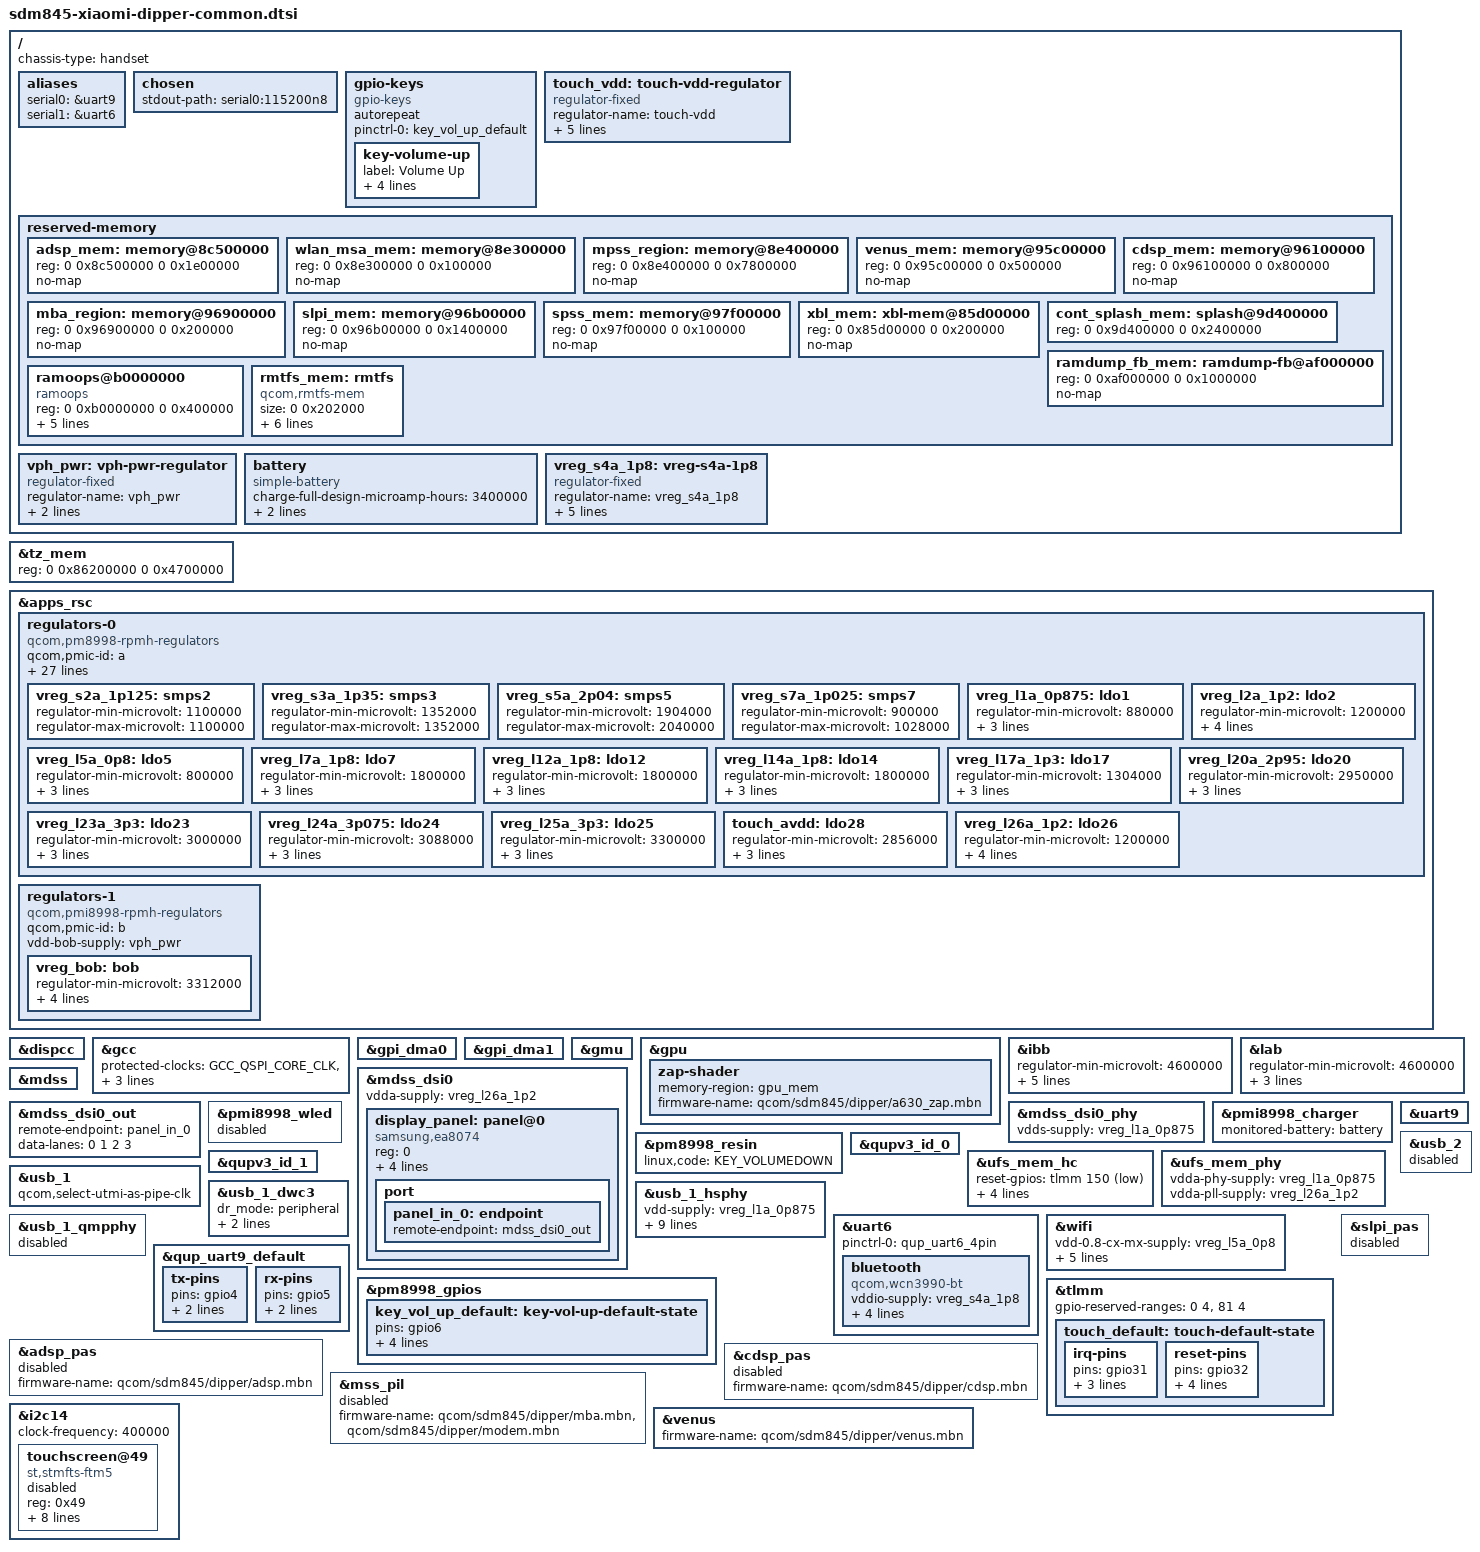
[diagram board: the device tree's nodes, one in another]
// SPDX-License-Identifier: GPL-2.0
/*
 * Xiaomi Mi 8 (dipper), shared v2/v2.1 board description.
 * Derived from Max Furman's dipper-mainline-port board description.
 * Copyright (c) 2026 Max Furman <taygoth@gmail.com>
 *
 * This source is compile-tested only. It is not a tested boot image.
 * Camera, audio, fuel gauge and Type-C role/PD support need separate
 * drivers/integration; do not enable placeholder nodes for them here.
 */

#include <dt-bindings/arm/qcom,ids.h>
#include <dt-bindings/firmware/qcom,scm.h>
#include <dt-bindings/gpio/gpio.h>
#include <dt-bindings/input/linux-event-codes.h>
#include <dt-bindings/interrupt-controller/irq.h>
#include <dt-bindings/phy/phy-qcom-qusb2.h>
#include <dt-bindings/pinctrl/qcom,pmic-gpio.h>
#include <dt-bindings/regulator/qcom,rpmh-regulator.h>
#include "sdm845.dtsi"
#include "pm8998.dtsi"
#include "pmi8998.dtsi"

/delete-node/ &xbl_mem;
/delete-node/ &rmtfs_mem;
/delete-node/ &adsp_mem;
/delete-node/ &wlan_msa_mem;
/delete-node/ &mpss_region;
/delete-node/ &venus_mem;
/delete-node/ &cdsp_mem;
/delete-node/ &mba_region;
/delete-node/ &slpi_mem;
/delete-node/ &spss_mem;

/ {
	chassis-type = "handset";

	aliases {
		serial0 = &uart9;
		serial1 = &uart6;
	};

	chosen {
		stdout-path = "serial0:115200n8";
	};

	gpio-keys {
		compatible = "gpio-keys";
		autorepeat;
		pinctrl-names = "default";
		pinctrl-0 = <&key_vol_up_default>;

		key-volume-up {
			label = "Volume Up";
			linux,code = <KEY_VOLUMEUP>;
			gpios = <&pm8998_gpios 6 GPIO_ACTIVE_LOW>;
			wakeup-source;
			debounce-interval = <15>;
		};
	};

	touch_vdd: touch-vdd-regulator {
		compatible = "regulator-fixed";
		regulator-name = "touch-vdd";
		regulator-min-microvolt = <1800000>;
		regulator-max-microvolt = <1800000>;
		gpio = <&tlmm 23 GPIO_ACTIVE_HIGH>;
		enable-active-high;
		startup-delay-us = <4000>;
	};

	reserved-memory {
		adsp_mem: memory@8c500000 {
			reg = <0 0x8c500000 0 0x1e00000>;
			no-map;
		};

		wlan_msa_mem: memory@8e300000 {
			reg = <0 0x8e300000 0 0x100000>;
			no-map;
		};

		mpss_region: memory@8e400000 {
			reg = <0 0x8e400000 0 0x7800000>;
			no-map;
		};

		venus_mem: memory@95c00000 {
			reg = <0 0x95c00000 0 0x500000>;
			no-map;
		};

		cdsp_mem: memory@96100000 {
			reg = <0 0x96100000 0 0x800000>;
			no-map;
		};

		mba_region: memory@96900000 {
			reg = <0 0x96900000 0 0x200000>;
			no-map;
		};

		slpi_mem: memory@96b00000 {
			reg = <0 0x96b00000 0 0x1400000>;
			no-map;
		};

		spss_mem: memory@97f00000 {
			reg = <0 0x97f00000 0 0x100000>;
			no-map;
		};

		/* Legacy sdm845.dtsi reserves both Mi 8 XBL megabytes. */
		xbl_mem: xbl-mem@85d00000 {
			reg = <0 0x85d00000 0 0x200000>;
			no-map;
		};

		/* Final dipper-p0.dtsi reservations, not a live framebuffer. */
		cont_splash_mem: splash@9d400000 {
			reg = <0 0x9d400000 0 0x2400000>;
		};

		ramdump_fb_mem: ramdump-fb@af000000 {
			reg = <0 0xaf000000 0 0x1000000>;
			no-map;
		};

		ramoops@b0000000 {
			compatible = "ramoops";
			reg = <0 0xb0000000 0 0x400000>;
			record-size = <0x40000>;
			console-size = <0x40000>;
			ftrace-size = <0x40000>;
			pmsg-size = <0x200000>;
			ecc-size = <0>;
		};

		/* Allocate guarded RMTFS buffers, not a guessed fixed address. */
		rmtfs_mem: rmtfs {
			compatible = "qcom,rmtfs-mem";
			size = <0 0x202000>;
			alignment = <0 0x1000>;
			alloc-ranges = <0 0xa0000000 0 0x20000000>;
			no-map;
			qcom,client-id = <1>;
			qcom,use-guard-pages;
			qcom,vmid = <QCOM_SCM_VMID_MSS_MSA>;
		};
	};

	vph_pwr: vph-pwr-regulator {
		compatible = "regulator-fixed";
		regulator-name = "vph_pwr";
		regulator-min-microvolt = <3700000>;
		regulator-max-microvolt = <3700000>;
	};

	battery: battery {
		compatible = "simple-battery";

		charge-full-design-microamp-hours = <3400000>;
		voltage-min-design-microvolt = <3400000>;
		voltage-max-design-microvolt = <4400000>;
	};

	vreg_s4a_1p8: vreg-s4a-1p8 {
		compatible = "regulator-fixed";
		regulator-name = "vreg_s4a_1p8";
		regulator-min-microvolt = <1800000>;
		regulator-max-microvolt = <1800000>;
		regulator-always-on;
		regulator-boot-on;
		vin-supply = <&vph_pwr>;
	};
};

&tz_mem {
	/* AOP/cmd-db/SMEM + this region cover the old removed_region. */
	reg = <0 0x86200000 0 0x4700000>;
};

&apps_rsc {
	regulators-0 {
		compatible = "qcom,pm8998-rpmh-regulators";
		qcom,pmic-id = "a";

		vdd-s1-supply = <&vph_pwr>;
		vdd-s2-supply = <&vph_pwr>;
		vdd-s3-supply = <&vph_pwr>;
		vdd-s4-supply = <&vph_pwr>;
		vdd-s5-supply = <&vph_pwr>;
		vdd-s6-supply = <&vph_pwr>;
		vdd-s7-supply = <&vph_pwr>;
		vdd-s8-supply = <&vph_pwr>;
		vdd-s9-supply = <&vph_pwr>;
		vdd-s10-supply = <&vph_pwr>;
		vdd-s11-supply = <&vph_pwr>;
		vdd-s12-supply = <&vph_pwr>;
		vdd-s13-supply = <&vph_pwr>;
		vdd-l1-l27-supply = <&vreg_s7a_1p025>;
		vdd-l2-l8-l17-supply = <&vreg_s3a_1p35>;
		vdd-l3-l11-supply = <&vreg_s7a_1p025>;
		vdd-l4-l5-supply = <&vreg_s7a_1p025>;
		vdd-l6-supply = <&vph_pwr>;
		vdd-l7-l12-l14-l15-supply = <&vreg_s5a_2p04>;
		vdd-l9-supply = <&vreg_bob>;
		vdd-l10-l23-l25-supply = <&vreg_bob>;
		vdd-l13-l19-l21-supply = <&vreg_bob>;
		vdd-l16-l28-supply = <&vreg_bob>;
		vdd-l18-l22-supply = <&vreg_bob>;
		vdd-l20-l24-supply = <&vreg_bob>;
		vdd-l26-supply = <&vreg_s3a_1p35>;
		vin-lvs-1-2-supply = <&vreg_s4a_1p8>;

		vreg_s2a_1p125: smps2 {
			regulator-min-microvolt = <1100000>;
			regulator-max-microvolt = <1100000>;
		};

		vreg_s3a_1p35: smps3 {
			regulator-min-microvolt = <1352000>;
			regulator-max-microvolt = <1352000>;
		};

		vreg_s5a_2p04: smps5 {
			regulator-min-microvolt = <1904000>;
			regulator-max-microvolt = <2040000>;
		};

		vreg_s7a_1p025: smps7 {
			regulator-min-microvolt = <900000>;
			regulator-max-microvolt = <1028000>;
		};

		vreg_l1a_0p875: ldo1 {
			regulator-min-microvolt = <880000>;
			regulator-max-microvolt = <880000>;
			regulator-initial-mode = <RPMH_REGULATOR_MODE_HPM>;
		};

		vreg_l2a_1p2: ldo2 {
			regulator-min-microvolt = <1200000>;
			regulator-max-microvolt = <1200000>;
			regulator-initial-mode = <RPMH_REGULATOR_MODE_HPM>;
			regulator-always-on;
		};

		vreg_l5a_0p8: ldo5 {
			regulator-min-microvolt = <800000>;
			regulator-max-microvolt = <800000>;
			regulator-initial-mode = <RPMH_REGULATOR_MODE_HPM>;
		};

		vreg_l7a_1p8: ldo7 {
			regulator-min-microvolt = <1800000>;
			regulator-max-microvolt = <1800000>;
			regulator-initial-mode = <RPMH_REGULATOR_MODE_HPM>;
		};

		vreg_l12a_1p8: ldo12 {
			regulator-min-microvolt = <1800000>;
			regulator-max-microvolt = <1800000>;
			regulator-initial-mode = <RPMH_REGULATOR_MODE_HPM>;
		};

		vreg_l14a_1p8: ldo14 {
			regulator-min-microvolt = <1800000>;
			regulator-max-microvolt = <1800000>;
			regulator-initial-mode = <RPMH_REGULATOR_MODE_HPM>;
		};

		vreg_l17a_1p3: ldo17 {
			regulator-min-microvolt = <1304000>;
			regulator-max-microvolt = <1304000>;
			regulator-initial-mode = <RPMH_REGULATOR_MODE_HPM>;
		};

		vreg_l20a_2p95: ldo20 {
			regulator-min-microvolt = <2950000>;
			regulator-max-microvolt = <2960000>;
			regulator-initial-mode = <RPMH_REGULATOR_MODE_HPM>;
		};

		vreg_l23a_3p3: ldo23 {
			regulator-min-microvolt = <3000000>;
			regulator-max-microvolt = <3312000>;
			regulator-initial-mode = <RPMH_REGULATOR_MODE_HPM>;
		};

		vreg_l24a_3p075: ldo24 {
			regulator-min-microvolt = <3088000>;
			regulator-max-microvolt = <3088000>;
			regulator-initial-mode = <RPMH_REGULATOR_MODE_HPM>;
		};

		vreg_l25a_3p3: ldo25 {
			regulator-min-microvolt = <3300000>;
			regulator-max-microvolt = <3312000>;
			regulator-initial-mode = <RPMH_REGULATOR_MODE_HPM>;
		};

		touch_avdd: ldo28 {
			regulator-min-microvolt = <2856000>;
			regulator-max-microvolt = <3008000>;
			regulator-initial-mode = <RPMH_REGULATOR_MODE_HPM>;
		};

		vreg_l26a_1p2: ldo26 {
			regulator-min-microvolt = <1200000>;
			regulator-max-microvolt = <1200000>;
			regulator-initial-mode = <RPMH_REGULATOR_MODE_HPM>;
			regulator-boot-on;
		};

	};

	regulators-1 {
		compatible = "qcom,pmi8998-rpmh-regulators";
		qcom,pmic-id = "b";

		vdd-bob-supply = <&vph_pwr>;

		vreg_bob: bob {
			regulator-min-microvolt = <3312000>;
			regulator-max-microvolt = <3600000>;
			regulator-initial-mode = <RPMH_REGULATOR_MODE_AUTO>;
			regulator-allow-bypass;
		};
	};
};

&dispcc {
	status = "okay";
};

&gcc {
	protected-clocks = <GCC_QSPI_CORE_CLK>,
			   <GCC_QSPI_CORE_CLK_SRC>,
			   <GCC_QSPI_CNOC_PERIPH_AHB_CLK>,
			   <GCC_LPASS_Q6_AXI_CLK>,
			   <GCC_LPASS_SWAY_CLK>;
};

&gpi_dma0 {
	status = "okay";
};

&gpi_dma1 {
	status = "okay";
};

&gmu {
	status = "okay";
};

&gpu {
	status = "okay";

	zap-shader {
		memory-region = <&gpu_mem>;
		firmware-name = "qcom/sdm845/dipper/a630_zap.mbn";
	};
};

&ibb {
	regulator-min-microvolt = <4600000>;
	regulator-max-microvolt = <6000000>;
	regulator-over-current-protection;
	regulator-pull-down;
	regulator-soft-start;
	qcom,discharge-resistor-kohms = <300>;
};

&lab {
	regulator-min-microvolt = <4600000>;
	regulator-max-microvolt = <6000000>;
	regulator-pull-down;
	regulator-soft-start;
};

&mdss {
	status = "okay";
};

&mdss_dsi0 {
	status = "okay";
	vdda-supply = <&vreg_l26a_1p2>;

	display_panel: panel@0 {
		compatible = "samsung,ea8074";
		reg = <0>;

		vddio-supply = <&vreg_l14a_1p8>;
		elvdd-supply = <&lab>;
		elvss-supply = <&ibb>;

		reset-gpios = <&tlmm 6 GPIO_ACTIVE_LOW>;

		status = "okay";

		port {
			panel_in_0: endpoint {
				remote-endpoint = <&mdss_dsi0_out>;
			};
		};
	};
};

&mdss_dsi0_out {
	remote-endpoint = <&panel_in_0>;
	data-lanes = <0 1 2 3>;
};

&mdss_dsi0_phy {
	status = "okay";
	vdds-supply = <&vreg_l1a_0p875>;
};

&pmi8998_charger {
	monitored-battery = <&battery>;

	status = "okay";
};

&pmi8998_wled {
	status = "disabled";
};

&pm8998_resin {
	linux,code = <KEY_VOLUMEDOWN>;
	status = "okay";
};

&qupv3_id_0 {
	status = "okay";
};

&qupv3_id_1 {
	status = "okay";
};

&uart9 {
	status = "okay";
};

&ufs_mem_hc {
	status = "okay";

	reset-gpios = <&tlmm 150 GPIO_ACTIVE_LOW>;

	vcc-supply = <&vreg_l20a_2p95>;
	vcc-max-microamp = <600000>;
	vccq2-supply = <&vreg_s4a_1p8>;
	vccq2-max-microamp = <600000>;

};

&ufs_mem_phy {
	status = "okay";

	vdda-phy-supply = <&vreg_l1a_0p875>;
	vdda-pll-supply = <&vreg_l26a_1p2>;
};

&usb_1 {
	status = "okay";
	qcom,select-utmi-as-pipe-clk;
};

&usb_1_dwc3 {
	/* No host/VBUS sourcing until PMI8998 Type-C is ported. */
	dr_mode = "peripheral";
	maximum-speed = "high-speed";
	phys = <&usb_1_hsphy>;
	phy-names = "usb2-phy";
};

&usb_1_hsphy {
	status = "okay";

	vdd-supply = <&vreg_l1a_0p875>;
	vdda-pll-supply = <&vreg_l12a_1p8>;
	vdda-phy-dpdm-supply = <&vreg_l24a_3p075>;

	qcom,imp-res-offset-value = <8>;
	qcom,hstx-trim-value = <QUSB2_V2_HSTX_TRIM_21_6_MA>;
	qcom,preemphasis-level = <QUSB2_V2_PREEMPHASIS_5_PERCENT>;
	qcom,preemphasis-width = <QUSB2_V2_PREEMPHASIS_WIDTH_HALF_BIT>;
};

&usb_1_qmpphy {
	status = "disabled";
};

&usb_2 {
	status = "disabled";
};

&uart6 {
	status = "okay";

	pinctrl-0 = <&qup_uart6_4pin>;

	bluetooth {
		compatible = "qcom,wcn3990-bt";

		vddio-supply = <&vreg_s4a_1p8>;
		vddxo-supply = <&vreg_l7a_1p8>;
		vddrf-supply = <&vreg_l17a_1p3>;
		vddch0-supply = <&vreg_l25a_3p3>;
		max-speed = <3200000>;
	};
};

&wifi {
	status = "okay";

	vdd-0.8-cx-mx-supply = <&vreg_l5a_0p8>;
	vdd-1.8-xo-supply = <&vreg_l7a_1p8>;
	vdd-1.3-rfa-supply = <&vreg_l17a_1p3>;
	vdd-3.3-ch0-supply = <&vreg_l25a_3p3>;
	vdd-3.3-ch1-supply = <&vreg_l23a_3p3>;

	qcom,ath10k-calibration-variant = "xiaomi_dipper";
};

&qup_uart9_default {
	tx-pins {
		pins = "gpio4";
		drive-strength = <2>;
		bias-disable;
	};

	rx-pins {
		pins = "gpio5";
		drive-strength = <2>;
		bias-pull-up;
	};
};

&pm8998_gpios {
	key_vol_up_default: key-vol-up-default-state {
		pins = "gpio6";
		function = "normal";
		input-enable;
		bias-pull-up;
		power-source = <0>;
	};
};

&tlmm {
	gpio-reserved-ranges = <0 4>, <81 4>;
};

/* Firmware names are contracts for the later Android firmware packaging. */
&adsp_pas {
	firmware-name = "qcom/sdm845/dipper/adsp.mbn";
	status = "disabled";
};

&cdsp_pas {
	firmware-name = "qcom/sdm845/dipper/cdsp.mbn";
	status = "disabled";
};

&mss_pil {
	firmware-name = "qcom/sdm845/dipper/mba.mbn",
			"qcom/sdm845/dipper/modem.mbn";
	status = "disabled";
};

&slpi_pas {
	status = "disabled";
};

&venus {
	firmware-name = "qcom/sdm845/dipper/venus.mbn";
	status = "okay";
};

&i2c14 {
	clock-frequency = <400000>;
	status = "okay";

	touchscreen@49 {
		compatible = "st,stmfts-ftm5";
		reg = <0x49>;
		interrupts-extended = <&tlmm 31 IRQ_TYPE_LEVEL_LOW>;
		reset-gpios = <&tlmm 32 GPIO_ACTIVE_LOW>;
		vdd-supply = <&touch_vdd>;
		avdd-supply = <&touch_avdd>;
		touchscreen-size-x = <1080>;
		touchscreen-size-y = <2248>;
		pinctrl-names = "default";
		pinctrl-0 = <&touch_default>;
		/* Confirm the actual board and resident firmware before testing. */
		status = "disabled";
	};
};

&tlmm {
	touch_default: touch-default-state {
		irq-pins {
			pins = "gpio31";
			function = "gpio";
			bias-pull-up;
			drive-strength = <2>;
		};

		reset-pins {
			pins = "gpio32";
			function = "gpio";
			output-low;
			bias-disable;
			drive-strength = <2>;
		};
	};
};
